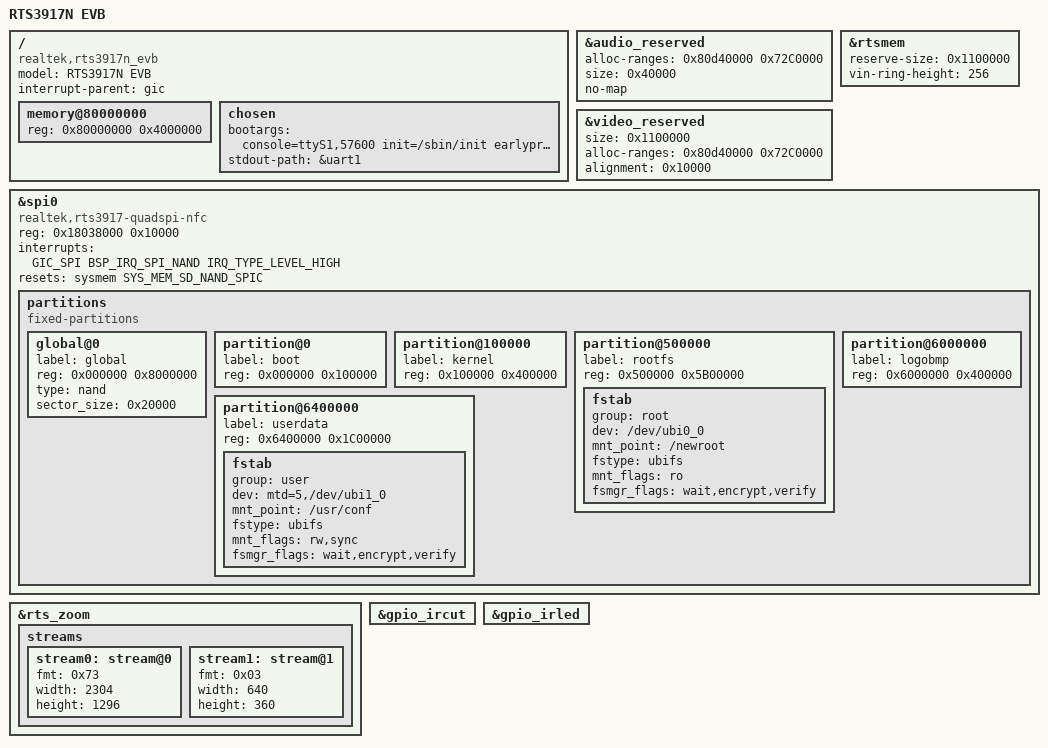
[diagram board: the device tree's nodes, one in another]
#include "rts3917n.dtsi"

/ {
	model = "RTS3917N EVB";
	compatible = "realtek,rts3917n_evb", "realtek,rts3917";

	#address-cells = <1>;
	#size-cells = <1>;
	interrupt-parent = <&gic>;

	memory@80000000 {
		device_type = "memory";
		reg = <0x80000000 0x4000000>;
	};

	chosen {
		bootargs = "console=ttyS1,57600 init=/sbin/init earlyprintk psci=enable ubi.mtd=3 root=ubi0_0 rootfstype=ubifs user_debug=31";
		stdout-path = &uart1;
	};
};

&audio_reserved {
	alloc-ranges = <0x80d40000 0x72C0000>;
	size = <0x40000>;
	no-map;
};

&video_reserved {
	size = <0x1100000>;
	alloc-ranges = <0x80d40000 0x72C0000>;
	alignment = <0x10000>;
};

&rtsmem {
	reserve-size = <0x1100000>;
	vin-ring-height = <256>;
};

&spi0 {
	status = "okay";
	compatible = "realtek,rts3917-quadspi-nfc";
	reg = <0x18038000 0x10000>;
	interrupts =	\
		<GIC_SPI BSP_IRQ_SPI_NAND IRQ_TYPE_LEVEL_HIGH>;
	resets = <&sysmem SYS_MEM_SD_NAND_SPIC>;
	reset-names = "spi-nand-sysmem-up";
	partitions {
		compatible = "fixed-partitions";
		#address-cells = <1>;
		#size-cells = <1>;
		global@0 {
			label = "global";
			reg = <0x000000 0x8000000>;	// nandflash size, 128M
			type = "nand";
			sector_size = <0x20000>;
		};

		partition@0 {
			label = "boot";
			reg = <0x000000 0x100000>; // 4*128K for uboot, 2*256K for env
		};

		partition@100000 {
			label = "kernel";
			reg = <0x100000 0x400000>; // 32*128K
		};

		partition@500000 {
			label = "rootfs";
			reg = <0x500000 0x5B00000>; // 728*128K

			fstab {
				group = "root";
				dev = "/dev/ubi0_0";
				mnt_point = "/newroot";
				fstype = "ubifs";
				mnt_flags = "ro";
				fsmgr_flags = "wait,encrypt,verify";
			};
		};

		partition@6000000 {
			label = "logobmp";
			reg = <0x6000000 0x400000>; // 32*128K
		};

		partition@6400000 {
			label = "userdata";
			reg = <0x6400000 0x1C00000>; // 224*128K

			fstab {
				group = "user";
				dev = "mtd=5,/dev/ubi1_0";
				mnt_point = "/usr/conf";
				fstype = "ubifs";
				mnt_flags = "rw,sync";
				fsmgr_flags = "wait,encrypt,verify";
			};
		};
	};
};

&rts_zoom {
	status = "okay";

	streams {
		stream0: stream@0 {
			fmt = <0x73>;
			width = <2304>;
			height = <1296>;
		};
		stream1: stream@1 {
			fmt = <0x03>;
			width = <640>;
			height = <360>;
		};
	};
};

&gpio_ircut {
	status = "okay";
};

&gpio_irled {
	status = "okay";
};
